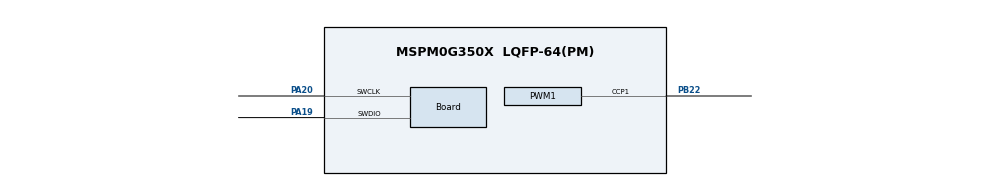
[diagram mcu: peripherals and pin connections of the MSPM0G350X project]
/**
 * @cliArgs --device "MSPM0G350X" --part "Default" --package "LQFP-64(PM)" --product "mspm0_sdk@2.02.00.05"
 * @versions {"tool":"1.21.0+3721"}
 */

/**
 * Import the modules used in this configuration.
 */
const PWM    = scripting.addModule("/ti/driverlib/PWM", {}, false);
const PWM1   = PWM.addInstance();
const SYSCTL = scripting.addModule("/ti/driverlib/SYSCTL");

/**
 * Write custom configuration values to the imported modules.
 */
PWM1.$name                      = "PWM_LED";
PWM1.clockDivider               = 8;
PWM1.timerStartTimer            = true;
PWM1.ccIndex                    = [1];
PWM1.peripheral.$assign         = "TIMG8";
PWM1.peripheral.ccp1Pin.$assign = "PB22";
PWM1.ccp1PinConfig.$name        = "ti_driverlib_gpio_GPIOPinGeneric1";
PWM1.PWM_CHANNEL_1.$name        = "ti_driverlib_pwm_PWMTimerCC0";

const Board                       = scripting.addModule("/ti/driverlib/Board", {}, false);
Board.peripheral.$assign          = "DEBUGSS";
Board.peripheral.swclkPin.$assign = "PA20";
Board.peripheral.swdioPin.$assign = "PA19";

SYSCTL.peripheral.$assign = "SYSCTL";

const ProjectConfig              = scripting.addModule("/ti/project_config/ProjectConfig", {}, false);
ProjectConfig.migrationCondition = true;
